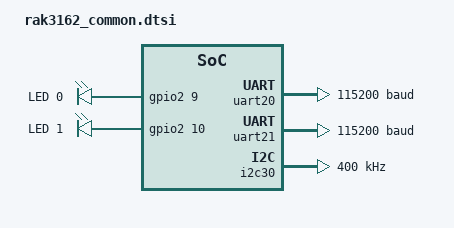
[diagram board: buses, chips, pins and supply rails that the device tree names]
/*
 * Copyright (c) 2026 RAK Wireless
 * SPDX-License-Identifier: Apache-2.0
 */

#include "rak3162-pinctrl.dtsi"

/ {
	leds {
		compatible = "gpio-leds";

		led0: led_0 {
			gpios = <&gpio2 9 GPIO_ACTIVE_HIGH>;
			label = "LED 0";
		};

		led1: led_1 {
			gpios = <&gpio2 10 GPIO_ACTIVE_HIGH>;
			label = "LED 1";
		};
	};

	aliases {
		led0 = &led0;
		led1 = &led1;
		watchdog0 = &wdt31;
	};
};

/* UART1 - Secondary UART, 115200 bps */
&uart20 {
	current-speed = <115200>;
	pinctrl-0 = <&uart20_default>;
	pinctrl-1 = <&uart20_sleep>;
	pinctrl-names = "default", "sleep";
};

/* UART0 - Debug UART, 115200 bps */
&uart21 {
	current-speed = <115200>;
	pinctrl-0 = <&uart21_default>;
	pinctrl-1 = <&uart21_sleep>;
	pinctrl-names = "default", "sleep";
};

/* I2C - 400kHz fast mode */
&i2c30 {
	pinctrl-0 = <&i2c30_default>;
	pinctrl-1 = <&i2c30_sleep>;
	pinctrl-names = "default", "sleep";
	clock-frequency = <400000>;
};

/* LoRa SPI bus (spi22) - CS/control GPIOs set in board DTS (onboard SX1262) */
&spi22 {
	pinctrl-0 = <&spi22_default>;
	pinctrl-1 = <&spi22_sleep>;
	pinctrl-names = "default", "sleep";
};

/* External/Reserved SPI bus (spi00) — CS on P2.05 (GPIO, active-low) */
&spi00 {
	max-frequency = <DT_FREQ_M(4)>;
	cs-gpios = <&gpio2 5 GPIO_ACTIVE_LOW>;
	pinctrl-0 = <&spi00_default>;
	pinctrl-1 = <&spi00_sleep>;
	pinctrl-names = "default", "sleep";
};

